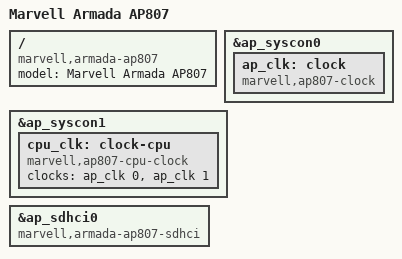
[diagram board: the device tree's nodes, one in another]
#define AP_NAME		ap807
#include "armada-ap80x.dtsi"
/ {
	model = "Marvell Armada AP807";
	compatible = "marvell,armada-ap807";
};
&ap_syscon0 {
	ap_clk: clock {
		compatible = "marvell,ap807-clock";
		#clock-cells = <1>;
	};
};
&ap_syscon1 {
	cpu_clk: clock-cpu {
		compatible = "marvell,ap807-cpu-clock";
		clocks = <&ap_clk 0>, <&ap_clk 1>;
		#clock-cells = <1>;
	};
};
&ap_sdhci0 {
	compatible = "marvell,armada-ap807-sdhci",
		     "marvell,armada-ap806-sdhci";  
};
